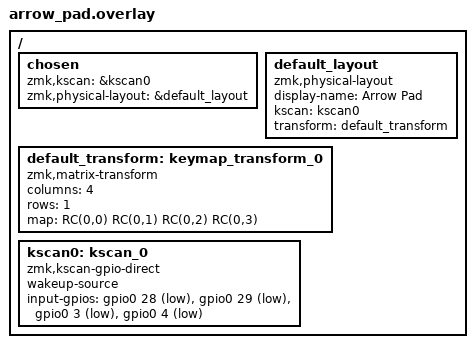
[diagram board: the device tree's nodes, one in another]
#include <dt-bindings/zmk/matrix_transform.h>
#include <dt-bindings/gpio/gpio.h>

/ {
    chosen {
        zmk,kscan = &kscan0;
        zmk,physical-layout = &default_layout;
    };

    default_layout: default_layout {
        compatible = "zmk,physical-layout";
        display-name = "Arrow Pad";
        kscan = <&kscan0>;
        transform = <&default_transform>;
    };

    default_transform: keymap_transform_0 {
        compatible = "zmk,matrix-transform";
        columns = <4>;
        rows = <1>;
        map = <
            RC(0,0) RC(0,1) RC(0,2) RC(0,3)
        >;
    };

    kscan0: kscan_0 {
        compatible = "zmk,kscan-gpio-direct";
        wakeup-source;
        input-gpios
            = <&gpio0 28 (GPIO_ACTIVE_LOW | GPIO_PULL_UP)>  /* UP    = D2 */
            , <&gpio0 29 (GPIO_ACTIVE_LOW | GPIO_PULL_UP)>  /* LEFT  = D3 */
            , <&gpio0 3  (GPIO_ACTIVE_LOW | GPIO_PULL_UP)>  /* DOWN  = D1 */
            , <&gpio0 4  (GPIO_ACTIVE_LOW | GPIO_PULL_UP)>  /* RIGHT = D4 */
            ;
    };
};
